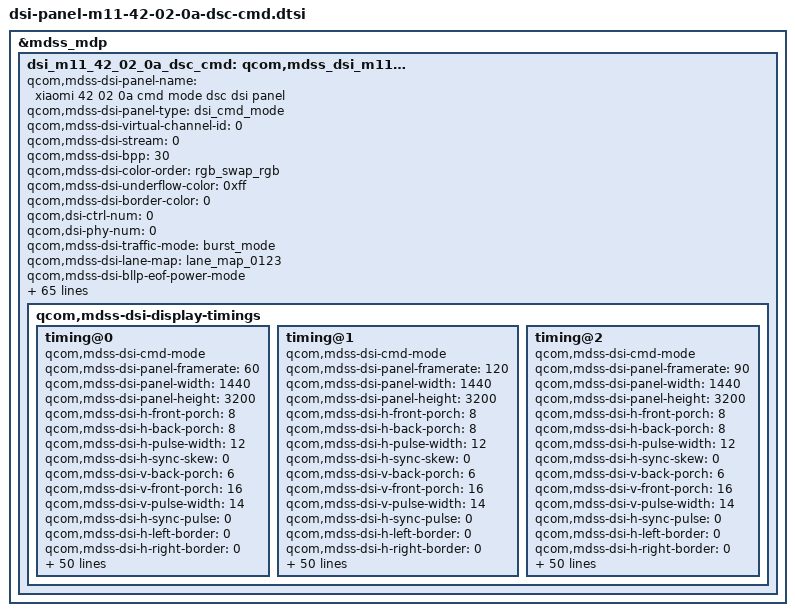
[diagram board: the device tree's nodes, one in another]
/* Panel Attention
 * 1.follow M11A, CCh must be 00 before 51h/26h/38h/39h/gamma change
 */

&mdss_mdp {
	dsi_m11_42_02_0a_dsc_cmd: qcom,mdss_dsi_m11_42_02_0a_dsc_cmd {
		qcom,mdss-dsi-panel-name = "xiaomi 42 02 0a cmd mode dsc dsi panel";
		qcom,mdss-dsi-panel-type = "dsi_cmd_mode";
		qcom,mdss-dsi-virtual-channel-id = <0>;
		qcom,mdss-dsi-stream = <0>;
		qcom,mdss-dsi-bpp = <30>;
		qcom,mdss-dsi-color-order = "rgb_swap_rgb";
		qcom,mdss-dsi-underflow-color = <0xff>;
		qcom,mdss-dsi-border-color = <0>;
		qcom,dsi-ctrl-num = <0>;
		qcom,dsi-phy-num = <0>;

		qcom,mdss-dsi-traffic-mode = "burst_mode";
		qcom,mdss-dsi-lane-map = "lane_map_0123";
		qcom,mdss-dsi-bllp-eof-power-mode;
		qcom,mdss-dsi-bllp-power-mode;
		qcom,mdss-dsi-lane-0-state;
		qcom,mdss-dsi-lane-1-state;
		qcom,mdss-dsi-lane-2-state;
		qcom,mdss-dsi-lane-3-state;
		qcom,mdss-dsi-dma-trigger = "trigger_sw";
		qcom,mdss-dsi-mdp-trigger = "none";
		qcom,mdss-dsi-reset-sequence = <1 11>, <0 1>, <1 11>;
		qcom,mdss-pan-physical-width-dimension = <695>;
		qcom,mdss-pan-physical-height-dimension = <1545>;
		qcom,mdss-dsi-te-pin-select = <1>;
		qcom,mdss-dsi-wr-mem-start = <0x2c>;
		qcom,mdss-dsi-wr-mem-continue = <0x3c>;
		qcom,mdss-dsi-te-dcs-command = <1>;
		qcom,mdss-dsi-te-check-enable;
		qcom,mdss-dsi-te-using-te-pin;
		qcom,mdss-dsi-tx-eot-append;
		qcom,mdss-dsi-lp11-init;

		qcom,mdss-dsi-bl-inverted-dbv;
		qcom,bl-update-flag = "delay_until_first_frame";

		qcom,mdss-dsi-panel-hdr-enabled;
		qcom,mdss-dsi-panel-hdr-color-primaries = <14500 15500 32000
			17000 15500 30000 8000 3000>;
		qcom,mdss-dsi-panel-peak-brightness = <4200000>;
		qcom,mdss-dsi-panel-blackness-level = <3230>;

		qcom,mdss-dsi-dma-schedule-line = <1>;
		qcom,mdss-dsi-dma-schedule-window = <50>;

		mi,panel-id = <0x004D3131 0x00420200>;
		mi,panel-ignore-esd-in-aod;

		qcom,mdss-dsi-display-timings {
			/* 60 Hz */
			timing@0 {
				qcom,mdss-dsi-cmd-mode;
				qcom,mdss-dsi-panel-framerate = <60>;
				qcom,mdss-dsi-panel-width = <1440>;
				qcom,mdss-dsi-panel-height = <3200>;
				qcom,mdss-dsi-h-front-porch = <8>;
				qcom,mdss-dsi-h-back-porch = <8>;
				qcom,mdss-dsi-h-pulse-width = <12>;
				qcom,mdss-dsi-h-sync-skew = <0>;
				qcom,mdss-dsi-v-back-porch = <6>;
				qcom,mdss-dsi-v-front-porch = <16>;
				qcom,mdss-dsi-v-pulse-width = <14>;
				qcom,mdss-dsi-h-sync-pulse = <0>;
				qcom,mdss-dsi-h-left-border = <0>;
				qcom,mdss-dsi-h-right-border = <0>;
				qcom,mdss-dsi-v-top-border = <0>;
				qcom,mdss-dsi-v-bottom-border = <0>;
				qcom,mdss-dsi-panel-clockrate = <1200000000>;
				qcom,mdss-dsi-panel-jitter = <0x5 0x1>;
				qcom,mdss-mdp-transfer-time-us = <7300>;
				qcom,mdss-dsi-on-command = [
					/* Source SOE control */
					39 00 00 40 00 00 06 F0 55 AA 52 08 00
					15 00 00 40 00 00 02 6F 1A
					15 00 00 40 00 00 02 C2 00
					/* Optimize Ocut stripes */
					39 00 00 40 00 00 06 F0 55 AA 52 08 01
					15 00 00 40 00 00 02 6F 0E
					15 00 00 40 00 00 02 B4 1F
					39 00 00 40 00 00 05 FF AA 55 A5 80
					15 00 00 40 00 00 02 6F 02
					15 00 00 00 00 00 02 F5 10
					/* Adjust the VGL voltage -9V */
					39 00 00 40 00 00 06 F0 55 AA 52 08 01
					39 00 00 00 00 00 03 B1 06 06
					/* Optimize rolling water ripple */
					39 00 00 40 00 00 06 F0 55 AA 52 08 01
					15 00 00 40 00 00 02 6F 01
					15 00 00 40 00 00 02 C4 E3
					39 00 00 40 00 00 05 FF AA 55 A5 80
					15 00 00 40 00 00 02 6F 18
					15 00 00 00 00 00 02 F8 19
					/* DVDD strong */
					39 00 00 40 00 00 06 F0 55 AA 52 08 01
					15 00 00 40 00 00 02 6F 01
					39 00 00 00 00 00 04 C5 0B 0B 0B
					/* About Demura */
					39 00 00 40 00 00 06 F0 55 AA 52 08 04
					15 00 00 00 00 00 02 C0 20
					/* Source OP Strong */
					39 00 00 40 00 00 06 F0 55 AA 52 08 00
					15 00 00 40 00 00 02 6F 20
					39 00 00 40 00 00 09 C6 55 55 55 55 55 55 55 55
					39 00 00 40 00 00 05 FF AA 55 A5 80
					15 00 00 40 00 00 02 6F 1B
					15 00 00 00 00 00 02 F4 55
					/* SRE optimize for IDLE */
					15 00 00 40 00 00 02 6F 19
					15 00 00 00 00 00 02 F2 00
					/* SDC clk setting */
					39 00 00 40 00 00 05 FF AA 55 A5 81
					15 00 00 40 00 00 02 6F 18
					15 00 00 00 00 00 02 FB 04
					/* skip mode source chopper setting */
					39 00 00 40 00 00 05 FF AA 55 A5 81
					15 00 00 40 00 00 02 6F 07
					15 00 00 00 00 00 02 FC 08
					/* CASET/RASET Setting 1440*3200 */
					39 00 00 40 00 00 05 2A 00 00 05 9F
					39 00 00 00 00 00 05 2B 00 00 0C 7F
					/* DSC Setting */
					15 00 00 40 00 00 02 90 03
					39 00 00 00 00 00 13 91
						AB A8 00 20 D2 00 02 86 03 5E 00 0A 03 5B 02 63
						10 F0
					/* TE ON */
					15 00 00 40 00 00 02 35 00
					15 00 00 00 00 00 02 5A 01
					/* VPorch-Ext Video */
					39 00 00 00 00 00 05 3B 00 18 00 10
					/* Remove AOD insert black frame */
					39 00 00 40 00 00 06 F0 55 AA 52 08 01
					39 00 00 40 00 00 06 D2 00 00 00 00 15
					15 00 00 40 00 00 02 6F 05
					39 00 00 40 00 00 04 D2 01 00 00
					15 00 00 40 00 00 02 6F 0E
					39 00 00 40 00 00 06 D2 00 00 10 13 32
					39 00 00 40 00 00 0B E4 80 03 00 00 00 00 00 00 00 33
					15 00 00 00 00 00 02 6F 0A
					39 00 00 00 00 00 07 E4 80 03 00 10 00 53
					/* Backlight On */
					15 00 00 00 00 00 02 53 20
					39 00 00 00 00 00 07 51 00 00 00 00 0F FF
					15 00 00 00 00 00 02 9C 01
					15 00 00 00 00 00 02 2C 00
					/* 60Hz GIR OFF*/
					15 00 00 40 00 00 02 2F 02
					15 00 00 40 00 00 02 5F 01
					15 00 00 40 00 00 02 26 00
					15 00 00 40 00 00 02 8B 00
					39 00 00 40 00 00 06 F0 55 AA 52 08 00
					15 00 00 40 00 00 02 6F 03
					15 00 00 40 00 00 02 C0 10
					15 00 00 40 00 00 02 6F 31
					15 00 00 40 00 00 02 DF 21
					39 00 00 40 00 00 06 F0 55 AA 52 08 02
					15 00 00 40 00 00 02 CC 30
					15 00 00 00 14 00 02 CE 01
					15 00 00 00 00 00 02 CC 00
					/* video trim */
					39 00 00 40 00 00 06 F0 55 AA 52 08 01
					39 00 00 40 00 00 0C C3 90 04 20 13 FF 00 04 20 0E FF 00
					15 00 00 00 00 00 02 6F 0B
					39 00 00 40 00 00 07 C3 06 30 1D 06 67 14
					15 00 00 00 00 00 02 6F 11
					39 00 00 40 00 00 07 C3 06 30 1D 06 67 14
					15 00 00 00 00 00 02 6F 17
					39 00 00 40 00 00 07 C3 06 30 1D 06 67 14
					15 00 00 00 00 00 02 6F 1D
					39 00 00 40 00 00 07 C3 06 30 1D 06 67 14
					15 00 00 00 00 00 02 6F 23
					39 00 00 40 00 00 07 C3 06 30 1D 06 67 14
					/* round on */
					39 00 00 40 00 00 06 F0 55 AA 52 08 07
					15 00 00 00 00 00 02 C0 B1
					/* Elvss */
					39 00 00 40 00 00 06 F0 55 AA 52 08 00
					15 00 00 40 00 00 02 6F 07
					39 00 00 40 00 00 05 B5 2A 1E 00 32
					39 00 00 40 00 00 1A B7
						40 40 41 42 43 44 45 46 47 48 49 4A 4B 4C 4D 4E
						4F 50 51 51 51 51 51 51 51
					15 00 00 40 00 00 02 6F 19
					39 00 00 40 00 00 0D B7
						17 88 99 AA BB CC DD EE FF FF FF FF
					15 00 00 40 00 00 02 6F 25
					39 00 00 00 00 00 19 B7
						BA FF 77 EF 67 DF 57 CF 47 BF 37 AF 27 9F 17 8F
						07 7F FF FF FF FF FF FF
					/* ESD Error Flag, Normal High, Error Low */
					39 00 00 40 00 00 06 F0 55 AA 52 08 00
					39 00 00 40 00 00 03 BE 47 45
					15 00 00 40 00 00 02 6F 05
					15 00 00 00 00 00 02 BE 88
					/* Sleep Out */
					05 00 00 00 78 00 02 11 00
					/* Display On */
					05 00 00 00 00 00 02 29 00
					/* Demura reload*/
					39 00 00 40 00 00 06 F0 55 AA 52 08 04
					15 00 00 40 00 00 02 6F 16
					15 00 00 40 00 00 02 D2 19
					15 00 00 40 00 00 02 6F 16
					15 00 00 40 00 00 02 D4 18
					15 00 00 40 00 00 02 6F 2F
					15 00 00 40 00 00 02 D2 28
					15 00 00 40 00 00 02 6F 2F
					15 00 00 40 00 00 02 D4 27
					15 00 00 40 00 00 02 6F 48
					15 00 00 40 00 00 02 D2 18
					15 00 00 40 00 00 02 6F 48
					15 00 00 00 00 00 02 D4 17
				];
				qcom,mdss-dsi-off-command = [
					39 00 00 00 14 00 02 28 00
					39 00 00 00 64 00 02 10 00
				];
				qcom,mdss-dsi-on-command-state = "dsi_lp_mode";
				qcom,mdss-dsi-off-command-state = "dsi_lp_mode";

				qcom,mdss-dsi-timing-switch-command = [
					/* 60 Hz cmd_1 */
					15 00 00 40 00 00 02 2F 02
					15 00 00 40 00 00 02 8B 00
					39 00 00 40 00 00 06 F0 55 AA 52 08 00
					15 00 00 40 00 00 02 6F 03
					15 00 00 40 00 00 02 C0 10
					15 00 00 40 00 00 02 6F 31
					15 00 00 40 00 00 02 DF 21
					39 00 00 40 00 00 06 F0 55 AA 52 08 02
					15 00 00 40 00 00 02 CC 30
					15 00 00 00 00 00 02 CE 01
				];
				qcom,mdss-dsi-timing-switch-command-update = <0xC0 4 1>, <0xDF 6 1>;
				qcom,mdss-dsi-timing-switch-command-state = "dsi_hs_mode";

				qcom,mdss-dsi-nolp-command = [
					/* gamma update */
					39 00 00 40 00 00 06 F0 55 AA 52 08 02
					15 00 00 00 00 00 02 CC 00
					/* AOD Mode off */
					39 00 00 40 00 00 03 51 00 00
					39 00 00 40 00 00 06 F0 55 AA 52 08 01
					15 00 00 40 00 00 02 6F 02
					15 00 00 40 00 00 02 B0 08
					15 00 00 40 00 00 02 E4 80
					15 00 00 40 00 00 02 6F 0A
					15 00 00 40 00 00 02 E4 80
					15 00 00 40 00 00 02 65 00
					15 00 00 00 00 00 02 38 00
					/* ERR Flag enable */
					39 00 00 40 00 00 06 F0 55 AA 52 08 00
					39 00 00 40 00 00 02 6F 01
					39 00 00 00 00 00 02 BE 45
				];
				qcom,mdss-dsi-nolp-command-update = <0x51 2 2>;
				qcom,mdss-dsi-nolp-command-state = "dsi_lp_mode";

				qcom,compression-mode = "dsc";
				qcom,mdss-dsc-version = <0x12>;
				qcom,mdss-dsc-scr-version = <0x0>;
				qcom,mdss-dsc-slice-height = <32>;
				qcom,mdss-dsc-slice-width = <720>;
				qcom,mdss-dsc-slice-per-pkt = <2>;
				qcom,mdss-dsc-bit-per-component = <10>;
				qcom,mdss-dsc-bit-per-pixel = <8>;
				qcom,mdss-dsc-block-prediction-enable;
			};

			/* 120 Hz */
			timing@1 {
				qcom,mdss-dsi-cmd-mode;
				qcom,mdss-dsi-panel-framerate = <120>;
				qcom,mdss-dsi-panel-width = <1440>;
				qcom,mdss-dsi-panel-height = <3200>;
				qcom,mdss-dsi-h-front-porch = <8>;
				qcom,mdss-dsi-h-back-porch = <8>;
				qcom,mdss-dsi-h-pulse-width = <12>;
				qcom,mdss-dsi-h-sync-skew = <0>;
				qcom,mdss-dsi-v-back-porch = <6>;
				qcom,mdss-dsi-v-front-porch = <16>;
				qcom,mdss-dsi-v-pulse-width = <14>;
				qcom,mdss-dsi-h-sync-pulse = <0>;
				qcom,mdss-dsi-h-left-border = <0>;
				qcom,mdss-dsi-h-right-border = <0>;
				qcom,mdss-dsi-v-top-border = <0>;
				qcom,mdss-dsi-v-bottom-border = <0>;
				qcom,mdss-dsi-panel-clockrate = <1200000000>;
				qcom,mdss-dsi-panel-jitter = <0x5 0x1>;
				qcom,mdss-mdp-transfer-time-us = <7300>;
				qcom,mdss-dsi-on-command = [
					/* Source SOE control */
					39 00 00 40 00 00 06 F0 55 AA 52 08 00
					15 00 00 40 00 00 02 6F 1A
					15 00 00 40 00 00 02 C2 00
					/* Optimize Ocut stripes */
					39 00 00 40 00 00 06 F0 55 AA 52 08 01
					15 00 00 40 00 00 02 6F 0E
					15 00 00 40 00 00 02 B4 1F
					39 00 00 40 00 00 05 FF AA 55 A5 80
					15 00 00 40 00 00 02 6F 02
					15 00 00 00 00 00 02 F5 10
					/* Adjust the VGL voltage -9V */
					39 00 00 40 00 00 06 F0 55 AA 52 08 01
					39 00 00 00 00 00 03 B1 06 06
					/* Optimize rolling water ripple */
					39 00 00 40 00 00 06 F0 55 AA 52 08 01
					15 00 00 40 00 00 02 6F 01
					15 00 00 40 00 00 02 C4 E3
					39 00 00 40 00 00 05 FF AA 55 A5 80
					15 00 00 40 00 00 02 6F 18
					15 00 00 00 00 00 02 F8 19
					/* DVDD strong */
					39 00 00 40 00 00 06 F0 55 AA 52 08 01
					15 00 00 40 00 00 02 6F 01
					39 00 00 00 00 00 04 C5 0B 0B 0B
					/* About Demura */
					39 00 00 40 00 00 06 F0 55 AA 52 08 04
					15 00 00 00 00 00 02 C0 20
					/* Source OP Strong */
					39 00 00 40 00 00 06 F0 55 AA 52 08 00
					15 00 00 40 00 00 02 6F 20
					39 00 00 40 00 00 09 C6 55 55 55 55 55 55 55 55
					39 00 00 40 00 00 05 FF AA 55 A5 80
					15 00 00 40 00 00 02 6F 1B
					15 00 00 00 00 00 02 F4 55
					/* SRE optimize for IDLE */
					15 00 00 40 00 00 02 6F 19
					15 00 00 00 00 00 02 F2 00
					/* SDC clk setting */
					39 00 00 40 00 00 05 FF AA 55 A5 81
					15 00 00 40 00 00 02 6F 18
					15 00 00 00 00 00 02 FB 04
					/* skip mode source chopper setting */
					39 00 00 40 00 00 05 FF AA 55 A5 81
					15 00 00 40 00 00 02 6F 07
					15 00 00 00 00 00 02 FC 08
					/* CASET/RASET Setting 1440*3200 */
					39 00 00 40 00 00 05 2A 00 00 05 9F
					39 00 00 00 00 00 05 2B 00 00 0C 7F
					/* DSC Setting */
					15 00 00 40 00 00 02 90 03
					39 00 00 00 00 00 13 91
						AB A8 00 20 D2 00 02 86 03 5E 00 0A 03 5B 02 63
						10 F0
					/* TE ON */
					15 00 00 40 00 00 02 35 00
					15 00 00 00 00 00 02 5A 01
					/* VPorch-Ext Video */
					39 00 00 00 00 00 05 3B 00 18 00 10
					/* Remove AOD insert black frame */
					39 00 00 40 00 00 06 F0 55 AA 52 08 01
					39 00 00 40 00 00 06 D2 00 00 00 00 15
					15 00 00 40 00 00 02 6F 05
					39 00 00 40 00 00 04 D2 01 00 00
					15 00 00 40 00 00 02 6F 0E
					39 00 00 40 00 00 06 D2 00 00 10 13 32
					39 00 00 40 00 00 0B E4 80 03 00 00 00 00 00 00 00 33
					15 00 00 00 00 00 02 6F 0A
					39 00 00 00 00 00 07 E4 80 03 00 10 00 53
					/* Backlight On */
					15 00 00 00 00 00 02 53 20
					39 00 00 00 00 00 07 51 00 00 00 00 0F FF
					15 00 00 00 00 00 02 9C 01
					15 00 00 00 00 00 02 2C 00
					/* 120Hz GIR OFF*/
					15 00 00 40 00 00 02 2F 00
					15 00 00 40 00 00 02 5F 01
					15 00 00 40 00 00 02 26 00
					15 00 00 40 00 00 02 8B 00
					39 00 00 40 00 00 06 F0 55 AA 52 08 00
					15 00 00 40 00 00 02 6F 03
					15 00 00 40 00 00 02 C0 10
					15 00 00 40 00 00 02 6F 31
					15 00 00 40 00 00 02 DF 20
					39 00 00 40 00 00 06 F0 55 AA 52 08 02
					15 00 00 40 00 00 02 CC 30
					15 00 00 00 14 00 02 CE 01
					15 00 00 00 00 00 02 CC 00
					/* video trim */
					39 00 00 40 00 00 06 F0 55 AA 52 08 01
					39 00 00 40 00 00 0C C3 90 04 20 13 FF 00 04 20 0E FF 00
					15 00 00 00 00 00 02 6F 0B
					39 00 00 40 00 00 07 C3 06 30 1D 06 67 14
					15 00 00 00 00 00 02 6F 11
					39 00 00 40 00 00 07 C3 06 30 1D 06 67 14
					15 00 00 00 00 00 02 6F 17
					39 00 00 40 00 00 07 C3 06 30 1D 06 67 14
					15 00 00 00 00 00 02 6F 1D
					39 00 00 40 00 00 07 C3 06 30 1D 06 67 14
					15 00 00 00 00 00 02 6F 23
					39 00 00 40 00 00 07 C3 06 30 1D 06 67 14
					/* round on */
					39 00 00 40 00 00 06 F0 55 AA 52 08 07
					15 00 00 00 00 00 02 C0 B1
					/* Elvss */
					39 00 00 40 00 00 06 F0 55 AA 52 08 00
					15 00 00 40 00 00 02 6F 07
					39 00 00 40 00 00 05 B5 2A 1E 00 32
					39 00 00 40 00 00 1A B7
						40 40 41 42 43 44 45 46 47 48 49 4A 4B 4C 4D 4E
						4F 50 51 51 51 51 51 51 51
					15 00 00 40 00 00 02 6F 19
					39 00 00 40 00 00 0D B7
						17 88 99 AA BB CC DD EE FF FF FF FF
					15 00 00 40 00 00 02 6F 25
					39 00 00 00 00 00 19 B7
						BA FF 77 EF 67 DF 57 CF 47 BF 37 AF 27 9F 17 8F
						07 7F FF FF FF FF FF FF
					/* ESD Error Flag, Normal High, Error Low */
					39 00 00 40 00 00 06 F0 55 AA 52 08 00
					39 00 00 40 00 00 03 BE 47 45
					15 00 00 40 00 00 02 6F 05
					15 00 00 00 00 00 02 BE 88
					/* Sleep Out */
					05 00 00 00 78 00 02 11 00
					/* Display On */
					05 00 00 00 00 00 02 29 00
					/* Demura reload*/
					39 00 00 40 00 00 06 F0 55 AA 52 08 04
					15 00 00 40 00 00 02 6F 16
					15 00 00 40 00 00 02 D2 19
					15 00 00 40 00 00 02 6F 16
					15 00 00 40 00 00 02 D4 18
					15 00 00 40 00 00 02 6F 2F
					15 00 00 40 00 00 02 D2 28
					15 00 00 40 00 00 02 6F 2F
					15 00 00 40 00 00 02 D4 27
					15 00 00 40 00 00 02 6F 48
					15 00 00 40 00 00 02 D2 18
					15 00 00 40 00 00 02 6F 48
					15 00 00 00 00 00 02 D4 17
				];
				qcom,mdss-dsi-off-command = [
					39 00 00 00 14 00 02 28 00
					39 00 00 00 64 00 02 10 00
				];
				qcom,mdss-dsi-on-command-state = "dsi_lp_mode";
				qcom,mdss-dsi-off-command-state = "dsi_lp_mode";

				qcom,mdss-dsi-timing-switch-command = [
					/* 120 Hz cmd_1 */
					15 00 00 40 00 00 02 2F 00
					15 00 00 40 00 00 02 8B 00
					39 00 00 40 00 00 06 F0 55 AA 52 08 00
					15 00 00 40 00 00 02 6F 03
					15 00 00 40 00 00 02 C0 10
					15 00 00 40 00 00 02 6F 31
					15 00 00 40 00 00 02 DF 20
					39 00 00 40 00 00 06 F0 55 AA 52 08 02
					15 00 00 40 00 00 02 CC 30
					15 00 00 00 00 00 02 CE 01
				];
				qcom,mdss-dsi-timing-switch-command-update = <0xC0 4 1>, <0xDF 6 1>;
				qcom,mdss-dsi-timing-switch-command-state = "dsi_hs_mode";

				qcom,mdss-dsi-nolp-command = [
					/* gamma update */
					39 00 00 40 00 00 06 F0 55 AA 52 08 02
					15 00 00 00 00 00 02 CC 00
					/* AOD Mode off */
					39 00 00 40 00 00 03 51 00 00
					39 00 00 40 00 00 06 F0 55 AA 52 08 01
					15 00 00 40 00 00 02 6F 02
					15 00 00 40 00 00 02 B0 08
					15 00 00 40 00 00 02 E4 80
					15 00 00 40 00 00 02 6F 0A
					15 00 00 40 00 00 02 E4 80
					15 00 00 40 00 00 02 65 00
					15 00 00 00 00 00 02 38 00
					/* ERR Flag enable */
					39 00 00 40 00 00 06 F0 55 AA 52 08 00
					39 00 00 40 00 00 02 6F 01
					39 00 00 00 00 00 02 BE 45
				];
				qcom,mdss-dsi-nolp-command-update = <0x51 2 2>;
				qcom,mdss-dsi-nolp-command-state = "dsi_lp_mode";

				qcom,compression-mode = "dsc";
				qcom,mdss-dsc-version = <0x12>;
				qcom,mdss-dsc-scr-version = <0x0>;
				qcom,mdss-dsc-slice-height = <32>;
				qcom,mdss-dsc-slice-width = <720>;
				qcom,mdss-dsc-slice-per-pkt = <2>;
				qcom,mdss-dsc-bit-per-component = <10>;
				qcom,mdss-dsc-bit-per-pixel = <8>;
				qcom,mdss-dsc-block-prediction-enable;
			};

			/* 90 Hz */
			timing@2 {
				qcom,mdss-dsi-cmd-mode;
				qcom,mdss-dsi-panel-framerate = <90>;
				qcom,mdss-dsi-panel-width = <1440>;
				qcom,mdss-dsi-panel-height = <3200>;
				qcom,mdss-dsi-h-front-porch = <8>;
				qcom,mdss-dsi-h-back-porch = <8>;
				qcom,mdss-dsi-h-pulse-width = <12>;
				qcom,mdss-dsi-h-sync-skew = <0>;
				qcom,mdss-dsi-v-back-porch = <6>;
				qcom,mdss-dsi-v-front-porch = <16>;
				qcom,mdss-dsi-v-pulse-width = <14>;
				qcom,mdss-dsi-h-sync-pulse = <0>;
				qcom,mdss-dsi-h-left-border = <0>;
				qcom,mdss-dsi-h-right-border = <0>;
				qcom,mdss-dsi-v-top-border = <0>;
				qcom,mdss-dsi-v-bottom-border = <0>;
				qcom,mdss-dsi-panel-clockrate = <1200000000>;
				qcom,mdss-dsi-panel-jitter = <0x5 0x1>;
				qcom,mdss-mdp-transfer-time-us = <7300>;
				qcom,mdss-dsi-on-command = [
					/* Source SOE control */
					39 00 00 40 00 00 06 F0 55 AA 52 08 00
					15 00 00 40 00 00 02 6F 1A
					15 00 00 40 00 00 02 C2 00
					/* Optimize Ocut stripes */
					39 00 00 40 00 00 06 F0 55 AA 52 08 01
					15 00 00 40 00 00 02 6F 0E
					15 00 00 40 00 00 02 B4 1F
					39 00 00 40 00 00 05 FF AA 55 A5 80
					15 00 00 40 00 00 02 6F 02
					15 00 00 00 00 00 02 F5 10
					/* Adjust the VGL voltage -9V */
					39 00 00 40 00 00 06 F0 55 AA 52 08 01
					39 00 00 00 00 00 03 B1 06 06
					/* Optimize rolling water ripple */
					39 00 00 40 00 00 06 F0 55 AA 52 08 01
					15 00 00 40 00 00 02 6F 01
					15 00 00 40 00 00 02 C4 E3
					39 00 00 40 00 00 05 FF AA 55 A5 80
					15 00 00 40 00 00 02 6F 18
					15 00 00 00 00 00 02 F8 19
					/* DVDD strong */
					39 00 00 40 00 00 06 F0 55 AA 52 08 01
					15 00 00 40 00 00 02 6F 01
					39 00 00 00 00 00 04 C5 0B 0B 0B
					/* About Demura */
					39 00 00 40 00 00 06 F0 55 AA 52 08 04
					15 00 00 00 00 00 02 C0 20
					/* Source OP Strong */
					39 00 00 40 00 00 06 F0 55 AA 52 08 00
					15 00 00 40 00 00 02 6F 20
					39 00 00 40 00 00 09 C6 55 55 55 55 55 55 55 55
					39 00 00 40 00 00 05 FF AA 55 A5 80
					15 00 00 40 00 00 02 6F 1B
					15 00 00 00 00 00 02 F4 55
					/* SRE optimize for IDLE */
					15 00 00 40 00 00 02 6F 19
					15 00 00 00 00 00 02 F2 00
					/* SDC clk setting */
					39 00 00 40 00 00 05 FF AA 55 A5 81
					15 00 00 40 00 00 02 6F 18
					15 00 00 00 00 00 02 FB 04
					/* skip mode source chopper setting */
					39 00 00 40 00 00 05 FF AA 55 A5 81
					15 00 00 40 00 00 02 6F 07
					15 00 00 00 00 00 02 FC 08
					/* CASET/RASET Setting 1440*3200 */
					39 00 00 40 00 00 05 2A 00 00 05 9F
					39 00 00 00 00 00 05 2B 00 00 0C 7F
					/* DSC Setting */
					15 00 00 40 00 00 02 90 03
					39 00 00 00 00 00 13 91
						AB A8 00 20 D2 00 02 86 03 5E 00 0A 03 5B 02 63
						10 F0
					/* TE ON */
					15 00 00 40 00 00 02 35 00
					15 00 00 00 00 00 02 5A 01
					/* VPorch-Ext Video */
					39 00 00 00 00 00 05 3B 00 18 00 10
					/* Remove AOD insert black frame */
					39 00 00 40 00 00 06 F0 55 AA 52 08 01
					39 00 00 40 00 00 06 D2 00 00 00 00 15
					15 00 00 40 00 00 02 6F 05
					39 00 00 40 00 00 04 D2 01 00 00
					15 00 00 40 00 00 02 6F 0E
					39 00 00 40 00 00 06 D2 00 00 10 13 32
					39 00 00 40 00 00 0B E4 80 03 00 00 00 00 00 00 00 33
					15 00 00 00 00 00 02 6F 0A
					39 00 00 00 00 00 07 E4 80 03 00 10 00 53
					/* Backlight On */
					15 00 00 00 00 00 02 53 20
					39 00 00 00 00 00 07 51 00 00 00 00 0F FF
					15 00 00 00 00 00 02 9C 01
					15 00 00 00 00 00 02 2C 00
					/* 90Hz GIR OFF*/
					15 00 00 40 00 00 02 2F 01
					15 00 00 40 00 00 02 5F 01
					15 00 00 40 00 00 02 26 00
					15 00 00 40 00 00 02 8B 10
					39 00 00 40 00 00 06 F0 55 AA 52 08 00
					15 00 00 40 00 00 02 6F 03
					15 00 00 40 00 00 02 C0 10
					15 00 00 40 00 00 02 6F 31
					15 00 00 40 00 00 02 DF 20
					39 00 00 40 00 00 06 F0 55 AA 52 08 02
					15 00 00 40 00 00 02 CC 30
					15 00 00 00 14 00 02 CE 01
					15 00 00 00 00 00 02 CC 00
					/* video trim */
					39 00 00 40 00 00 06 F0 55 AA 52 08 01
					39 00 00 40 00 00 0C C3 90 04 20 13 FF 00 04 20 0E FF 00
					15 00 00 00 00 00 02 6F 0B
					39 00 00 40 00 00 07 C3 06 30 1D 06 67 14
					15 00 00 00 00 00 02 6F 11
					39 00 00 40 00 00 07 C3 06 30 1D 06 67 14
					15 00 00 00 00 00 02 6F 17
					39 00 00 40 00 00 07 C3 06 30 1D 06 67 14
					15 00 00 00 00 00 02 6F 1D
					39 00 00 40 00 00 07 C3 06 30 1D 06 67 14
					15 00 00 00 00 00 02 6F 23
					39 00 00 40 00 00 07 C3 06 30 1D 06 67 14
					/* round on */
					39 00 00 40 00 00 06 F0 55 AA 52 08 07
					15 00 00 00 00 00 02 C0 B1
					/* Elvss */
					39 00 00 40 00 00 06 F0 55 AA 52 08 00
					15 00 00 40 00 00 02 6F 07
					39 00 00 40 00 00 05 B5 2A 1E 00 32
					39 00 00 40 00 00 1A B7
						40 40 41 42 43 44 45 46 47 48 49 4A 4B 4C 4D 4E
						4F 50 51 51 51 51 51 51 51
					15 00 00 40 00 00 02 6F 19
					39 00 00 40 00 00 0D B7
						17 88 99 AA BB CC DD EE FF FF FF FF
					15 00 00 40 00 00 02 6F 25
					39 00 00 00 00 00 19 B7
						BA FF 77 EF 67 DF 57 CF 47 BF 37 AF 27 9F 17 8F
						07 7F FF FF FF FF FF FF
					/* ESD Error Flag, Normal High, Error Low */
					39 00 00 40 00 00 06 F0 55 AA 52 08 00
					39 00 00 40 00 00 03 BE 47 45
					15 00 00 40 00 00 02 6F 05
					15 00 00 00 00 00 02 BE 88
					/* Sleep Out */
					05 00 00 00 78 00 02 11 00
					/* Display On */
					05 00 00 00 00 00 02 29 00
					/* Demura reload*/
					39 00 00 40 00 00 06 F0 55 AA 52 08 04
					15 00 00 40 00 00 02 6F 16
					15 00 00 40 00 00 02 D2 19
					15 00 00 40 00 00 02 6F 16
					15 00 00 40 00 00 02 D4 18
					15 00 00 40 00 00 02 6F 2F
					15 00 00 40 00 00 02 D2 28
					15 00 00 40 00 00 02 6F 2F
					15 00 00 40 00 00 02 D4 27
					15 00 00 40 00 00 02 6F 48
					15 00 00 40 00 00 02 D2 18
					15 00 00 40 00 00 02 6F 48
					15 00 00 00 00 00 02 D4 17
				];
				qcom,mdss-dsi-off-command = [
					39 00 00 00 14 00 02 28 00
					39 00 00 00 64 00 02 10 00
				];
				qcom,mdss-dsi-on-command-state = "dsi_lp_mode";
				qcom,mdss-dsi-off-command-state = "dsi_lp_mode";

				qcom,mdss-dsi-timing-switch-command = [
					/* 90 Hz cmd_1 */
					15 00 00 40 00 00 02 2F 01
					15 00 00 40 00 00 02 8B 10
					39 00 00 40 00 00 06 F0 55 AA 52 08 00
					15 00 00 40 00 00 02 6F 03
					15 00 00 40 00 00 02 C0 10
					15 00 00 40 00 00 02 6F 31
					15 00 00 40 00 00 02 DF 20
					39 00 00 40 00 00 06 F0 55 AA 52 08 02
					15 00 00 40 00 00 02 CC 30
					15 00 00 00 00 00 02 CE 01
				];
				qcom,mdss-dsi-timing-switch-command-update = <0xC0 4 1>, <0xDF 6 1>;
				qcom,mdss-dsi-timing-switch-command-state = "dsi_hs_mode";

				qcom,mdss-dsi-nolp-command = [
					/* gamma update */
					39 00 00 40 00 00 06 F0 55 AA 52 08 02
					15 00 00 00 00 00 02 CC 00
					/* AOD Mode off */
					39 00 00 40 00 00 03 51 00 00
					39 00 00 40 00 00 06 F0 55 AA 52 08 01
					15 00 00 40 00 00 02 6F 02
					15 00 00 40 00 00 02 B0 08
					15 00 00 40 00 00 02 E4 80
					15 00 00 40 00 00 02 6F 0A
					15 00 00 40 00 00 02 E4 80
					15 00 00 40 00 00 02 65 00
					15 00 00 00 00 00 02 38 00
					/* ERR Flag enable */
					39 00 00 40 00 00 06 F0 55 AA 52 08 00
					39 00 00 40 00 00 02 6F 01
					39 00 00 00 00 00 02 BE 45
				];
				qcom,mdss-dsi-nolp-command-update = <0x51 2 2>;
				qcom,mdss-dsi-nolp-command-state = "dsi_lp_mode";

				qcom,compression-mode = "dsc";
				qcom,mdss-dsc-version = <0x12>;
				qcom,mdss-dsc-scr-version = <0x0>;
				qcom,mdss-dsc-slice-height = <32>;
				qcom,mdss-dsc-slice-width = <720>;
				qcom,mdss-dsc-slice-per-pkt = <2>;
				qcom,mdss-dsc-bit-per-component = <10>;
				qcom,mdss-dsc-bit-per-pixel = <8>;
				qcom,mdss-dsc-block-prediction-enable;
			};
		};
	};
};

&dsi_m11_42_02_0a_dsc_cmd {
	/* IRQF_ONESHOT | IRQF_TRIGGER_LOW */
	mi,esd-err-irq-gpio = <&tlmm 49 0x2008>;

	mi,mdss-dsi-panel-wp-read-command = [06 01 00 01 00 00 01 A3];
	mi,mdss-dsi-panel-wp-read-command-state = "dsi_lp_mode";
	mi,mdss-dsi-panel-wp-read-length = <8>;

	mi,ddic-round-corner-enabled;

	mi,local-hbm-enabled;
	mi,local-hbm-white-1000nit-update-flag;
	mi,local-hbm-white-110nit-update-flag;
	mi,local-hbm-alpha-ctrl-aa-area;
	mi,local-hbm-ctrl-df-reg;
	mi,local-hbm-ui-ready-delay-num-frame = <4>; /* 4 frame */
	mi,fod-low-brightness-clone-threshold = <200>;
	mi,fod-low-brightness-lux-threshold = <3>;
	mi,need-fod-animal-in-normal-enabled;

	mi,doze-hbm-dbv-level = <252>;
	mi,doze-lbm-dbv-level = <20>;
	mi,max-brightness-clone = <16383>;
	mi,normal-max-brightness-clone = <8191>;

	mi,mdss-dsi-fac-bl-max-level = <2047>;
	mi,mdss-fac-brightness-max-level = <2047>;
	mi,hbm-bl-min-level = <1>;
	mi,hbm-bl-max-level = <2047>;

	mi,thermal-dimming-flag;
	mi,disable-ic-dimming-flag;
	mi,panel-on-dimming-delay = <120>;

	mi,flatmode-status-check-enabled;
	mi,mdss-dsi-panel-flatmode-status-command = [
		06 01 00 01 00 00 01 5F
	];
	mi,mdss-dsi-panel-flatmode-status-command-state = "dsi_lp_mode";
	mi,mdss-dsi-panel-flatmode-status-read-length = <1>;
	mi,mdss-dsi-panel-flatmode-on-status-value = <0x00>;

	qcom,mdss-dsi-display-timings {
		timing@0{ /* 60 hz */
			#include "dsi-panel-m11-42-02-0a-dsc-cmd-common.dtsi"
			/*<flat on gamma, flat off gamma>*/
			mi,mdss-flat-status-control-gamma-cfg = <0x32 0x10>;
			mi,mdss-flat-status-control-lhbm-gamma-cfg = <0x23 0x21>;

			mi,mdss-dsi-flat-mode-on-command = [
				/* 60hz gir cmd_1 */
				15 00 00 00 00 00 02 2F 02
				15 00 00 60 00 00 02 5F 00
				15 00 00 60 00 00 02 26 02
				15 00 00 60 00 00 02 8B 00
				39 00 00 60 00 00 06 F0 55 AA 52 08 00
				15 00 00 60 00 00 02 6F 03
				15 00 00 60 00 00 02 C0 32
				15 00 00 60 00 00 02 6F 31
				15 00 00 60 00 00 02 DF 23
				39 00 00 60 00 00 06 F0 55 AA 52 08 02
				15 00 00 60 00 00 02 CC 30
				15 00 00 20 14 00 02 CE 01
			];
			mi,mdss-dsi-flat-mode-on-command-state = "dsi_lp_mode";

			mi,mdss-dsi-flat-mode-on-sec-command = [
				/* 60hz gir cmd_2 */
				39 00 00 00 00 00 06 F0 55 AA 52 08 02
				15 00 00 00 00 00 02 CC 00
			];
			mi,mdss-dsi-flat-mode-on-sec-command-state = "dsi_lp_mode";

			mi,mdss-dsi-flat-mode-off-command = [
				/* 60hz gir cmd_1 */
				15 00 00 00 00 00 02 2F 02
				15 00 00 60 00 00 02 5F 01
				15 00 00 60 00 00 02 26 00
				15 00 00 60 00 00 02 8B 00
				39 00 00 60 00 00 06 F0 55 AA 52 08 00
				15 00 00 60 00 00 02 6F 03
				15 00 00 60 00 00 02 C0 10
				15 00 00 60 00 00 02 6F 31
				15 00 00 60 00 00 02 DF 21
				39 00 00 60 00 00 06 F0 55 AA 52 08 02
				15 00 00 60 00 00 02 CC 30
				15 00 00 20 14 00 02 CE 01
			];
			mi,mdss-dsi-flat-mode-off-command-state = "dsi_lp_mode";

			mi,mdss-dsi-flat-mode-off-sec-command = [
				/* 60hz gir cmd_2 */
				39 00 00 00 00 00 06 F0 55 AA 52 08 02
				15 00 00 00 00 00 02 CC 00
			];
			mi,mdss-dsi-flat-mode-off-sec-command-state = "dsi_lp_mode";
		};

		timing@1{ /* 120 hz */
			#include "dsi-panel-m11-42-02-0a-dsc-cmd-common.dtsi"
			/*<flat on gamma, flat off gamma>*/
			mi,mdss-flat-status-control-gamma-cfg = <0x32 0x10>;
			mi,mdss-flat-status-control-lhbm-gamma-cfg = <0x22 0x20>;

			mi,mdss-dsi-flat-mode-on-command = [
				/* 120hz gir cmd_1 */
				15 00 00 00 00 00 02 2F 00
				15 00 00 60 00 00 02 5F 00
				15 00 00 60 00 00 02 26 02
				15 00 00 60 00 00 02 8B 00
				39 00 00 60 00 00 06 F0 55 AA 52 08 00
				15 00 00 60 00 00 02 6F 03
				15 00 00 60 00 00 02 C0 32
				15 00 00 60 00 00 02 6F 31
				15 00 00 60 00 00 02 DF 22
				39 00 00 60 00 00 06 F0 55 AA 52 08 02
				15 00 00 60 00 00 02 CC 30
				15 00 00 20 14 00 02 CE 01
			];
			mi,mdss-dsi-flat-mode-on-command-state = "dsi_lp_mode";

			mi,mdss-dsi-flat-mode-on-sec-command = [
				/* 120hz gir cmd_2 */
				39 00 00 00 00 00 06 F0 55 AA 52 08 02
				15 00 00 00 00 00 02 CC 00
			];
			mi,mdss-dsi-flat-mode-on-sec-command-state = "dsi_lp_mode";

			mi,mdss-dsi-flat-mode-off-command = [
				/* 120hz gir cmd_1 */
				15 00 00 00 00 00 02 2F 00
				15 00 00 60 00 00 02 5F 01
				15 00 00 60 00 00 02 26 00
				15 00 00 60 00 00 02 8B 00
				39 00 00 60 00 00 06 F0 55 AA 52 08 00
				15 00 00 60 00 00 02 6F 03
				15 00 00 60 00 00 02 C0 10
				15 00 00 60 00 00 02 6F 31
				15 00 00 60 00 00 02 DF 20
				39 00 00 60 00 00 06 F0 55 AA 52 08 02
				15 00 00 60 00 00 02 CC 30
				15 00 00 20 14 00 02 CE 01
			];
			mi,mdss-dsi-flat-mode-off-command-state = "dsi_lp_mode";

			mi,mdss-dsi-flat-mode-off-sec-command = [
				/* 120hz gir cmd_2 */
				39 00 00 00 00 00 06 F0 55 AA 52 08 02
				15 00 00 00 00 00 02 CC 00
			];
			mi,mdss-dsi-flat-mode-off-sec-command-state = "dsi_lp_mode";
		};

		timing@2{ /* 90 hz */
			#include "dsi-panel-m11-42-02-0a-dsc-cmd-common.dtsi"
			/*<flat on gamma, flat off gamma>*/
			mi,mdss-flat-status-control-gamma-cfg = <0x32 0x10>;
			mi,mdss-flat-status-control-lhbm-gamma-cfg = <0x22 0x20>;

			mi,mdss-dsi-flat-mode-on-command = [
				/* 90hz gir cmd_1 */
				15 00 00 00 00 00 02 2F 01
				15 00 00 60 00 00 02 5F 00
				15 00 00 60 00 00 02 26 02
				15 00 00 60 00 00 02 8B 10
				39 00 00 60 00 00 06 F0 55 AA 52 08 00
				15 00 00 60 00 00 02 6F 03
				15 00 00 60 00 00 02 C0 32
				15 00 00 60 00 00 02 6F 31
				15 00 00 60 00 00 02 DF 22
				39 00 00 60 00 00 06 F0 55 AA 52 08 02
				15 00 00 60 00 00 02 CC 30
				15 00 00 20 14 00 02 CE 01
			];
			mi,mdss-dsi-flat-mode-on-command-state = "dsi_lp_mode";

			mi,mdss-dsi-flat-mode-on-sec-command = [
				/* 90hz gir cmd_2 */
				39 00 00 00 00 00 06 F0 55 AA 52 08 02
				15 00 00 00 00 00 02 CC 00
			];
			mi,mdss-dsi-flat-mode-on-sec-command-state = "dsi_lp_mode";

			mi,mdss-dsi-flat-mode-off-command = [
				/* 90hz gir cmd_1 */
				15 00 00 00 00 00 02 2F 01
				15 00 00 60 00 00 02 5F 01
				15 00 00 60 00 00 02 26 00
				15 00 00 60 00 00 02 8B 10
				39 00 00 60 00 00 06 F0 55 AA 52 08 00
				15 00 00 60 00 00 02 6F 03
				15 00 00 60 00 00 02 C0 10
				15 00 00 60 00 00 02 6F 31
				15 00 00 60 00 00 02 DF 20
				39 00 00 60 00 00 06 F0 55 AA 52 08 02
				15 00 00 60 00 00 02 CC 30
				15 00 00 20 14 00 02 CE 01
			];
			mi,mdss-dsi-flat-mode-off-command-state = "dsi_lp_mode";

			mi,mdss-dsi-flat-mode-off-sec-command = [
				/* 90hz gir cmd_2 */
				39 00 00 00 00 00 06 F0 55 AA 52 08 02
				15 00 00 00 00 00 02 CC 00
			];
			mi,mdss-dsi-flat-mode-off-sec-command-state = "dsi_lp_mode";
		};
	};
};
